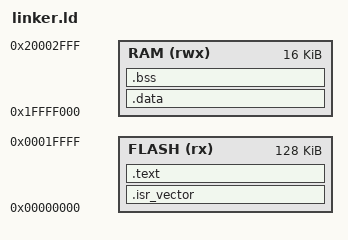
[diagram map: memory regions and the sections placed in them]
MEMORY
{
    FLASH (rx)  : ORIGIN = 0x00000000, LENGTH = 128K
    RAM   (rwx) : ORIGIN = 0x1FFFF000, LENGTH = 16K
}

_estack = ORIGIN(RAM) + LENGTH(RAM);

SECTIONS
{
    .isr_vector :
    {
        KEEP(*(.isr_vector))
    } > FLASH

    .text :
    {
        *(.text*)
        *(.rodata*)
    } > FLASH

    _sidata = LOADADDR(.data);

    .data : AT (_sidata)
    {
        _sdata = .;
        *(.data*)
        _edata = .;
    } > RAM

    .bss :
    {
        _sbss = .;
        *(.bss*)
        *(COMMON)
        _ebss = .;
    } > RAM
}
